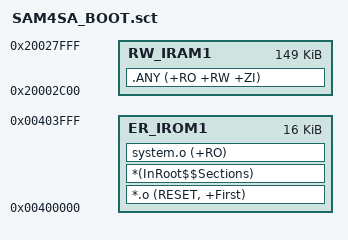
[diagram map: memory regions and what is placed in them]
; *************************************************************
; *** Scatter-Loading Description File generated by uVision ***
; *************************************************************

LR_IROM1 0x00400000 0x00004000  {    ; load region size_region

  ER_IROM1 0x00400000 0x00004000  {  ; load address = execution address
   *.o (RESET, +First)
   *(InRoot$$Sections)
    system.o (+RO)
  }
  RW_IRAM1 0x20002C00 0x00025400  {  ; RW data
   .ANY (+RO +RW +ZI)
  }
}


